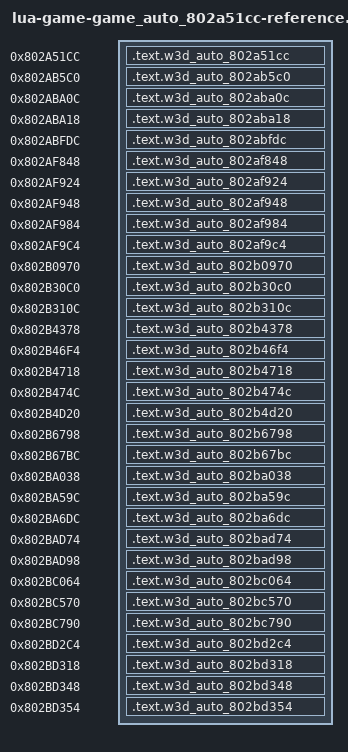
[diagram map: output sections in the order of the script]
/* Generated reference-only placements. All bodies are source-built. */
OUTPUT_FORMAT("elf32-powerpc")
OUTPUT_ARCH(powerpc)
ENTRY(w3d_auto_802a51cc)
_SDA_BASE_ = 0x804b2540;
_SDA2_BASE_ = 0x804c2540;
fn_8015FD1C = 0x8015fd1c;
fn_802B0668 = 0x802b0668;
fn_802B0990 = 0x802b0990;
fn_802B0FEC = 0x802b0fec;
fn_802B15E0 = 0x802b15e0;
fn_802B16C4 = 0x802b16c4;
fn_802B1BD0 = 0x802b1bd0;
fn_802B1F98 = 0x802b1f98;
fn_802B222C = 0x802b222c;
fn_802B2344 = 0x802b2344;
fn_802B38D4 = 0x802b38d4;
fn_802B4E10 = 0x802b4e10;
fn_802B9DE4 = 0x802b9de4;
fn_802BC1D0 = 0x802bc1d0;
fn_802BC1D4 = 0x802bc1d4;
fn_802BC570 = 0x802bc570;
fn_802BC5AC = 0x802bc5ac;
fn_802BC600 = 0x802bc600;
fn_802BD354 = 0x802bd354;
fn_802BDD24 = 0x802bdd24;
fn_802BFC64 = 0x802bfc64;
fn_80316270 = 0x80316270;
SECTIONS {
  .text.w3d_auto_802a51cc 0x802a51cc : { *(.text.w3d_auto_802a51cc) }
  .text.w3d_auto_802ab5c0 0x802ab5c0 : { *(.text.w3d_auto_802ab5c0) }
  .text.w3d_auto_802aba0c 0x802aba0c : { *(.text.w3d_auto_802aba0c) }
  .text.w3d_auto_802aba18 0x802aba18 : { *(.text.w3d_auto_802aba18) }
  .text.w3d_auto_802abfdc 0x802abfdc : { *(.text.w3d_auto_802abfdc) }
  .text.w3d_auto_802af848 0x802af848 : { *(.text.w3d_auto_802af848) }
  .text.w3d_auto_802af924 0x802af924 : { *(.text.w3d_auto_802af924) }
  .text.w3d_auto_802af948 0x802af948 : { *(.text.w3d_auto_802af948) }
  .text.w3d_auto_802af984 0x802af984 : { *(.text.w3d_auto_802af984) }
  .text.w3d_auto_802af9c4 0x802af9c4 : { *(.text.w3d_auto_802af9c4) }
  .text.w3d_auto_802b0970 0x802b0970 : { *(.text.w3d_auto_802b0970) }
  .text.w3d_auto_802b30c0 0x802b30c0 : { *(.text.w3d_auto_802b30c0) }
  .text.w3d_auto_802b310c 0x802b310c : { *(.text.w3d_auto_802b310c) }
  .text.w3d_auto_802b4378 0x802b4378 : { *(.text.w3d_auto_802b4378) }
  .text.w3d_auto_802b46f4 0x802b46f4 : { *(.text.w3d_auto_802b46f4) }
  .text.w3d_auto_802b4718 0x802b4718 : { *(.text.w3d_auto_802b4718) }
  .text.w3d_auto_802b474c 0x802b474c : { *(.text.w3d_auto_802b474c) }
  .text.w3d_auto_802b4d20 0x802b4d20 : { *(.text.w3d_auto_802b4d20) }
  .text.w3d_auto_802b6798 0x802b6798 : { *(.text.w3d_auto_802b6798) }
  .text.w3d_auto_802b67bc 0x802b67bc : { *(.text.w3d_auto_802b67bc) }
  .text.w3d_auto_802ba038 0x802ba038 : { *(.text.w3d_auto_802ba038) }
  .text.w3d_auto_802ba59c 0x802ba59c : { *(.text.w3d_auto_802ba59c) }
  .text.w3d_auto_802ba6dc 0x802ba6dc : { *(.text.w3d_auto_802ba6dc) }
  .text.w3d_auto_802bad74 0x802bad74 : { *(.text.w3d_auto_802bad74) }
  .text.w3d_auto_802bad98 0x802bad98 : { *(.text.w3d_auto_802bad98) }
  .text.w3d_auto_802bc064 0x802bc064 : { *(.text.w3d_auto_802bc064) }
  .text.w3d_auto_802bc570 0x802bc570 : { *(.text.w3d_auto_802bc570) }
  .text.w3d_auto_802bc790 0x802bc790 : { *(.text.w3d_auto_802bc790) }
  .text.w3d_auto_802bd2c4 0x802bd2c4 : { *(.text.w3d_auto_802bd2c4) }
  .text.w3d_auto_802bd318 0x802bd318 : { *(.text.w3d_auto_802bd318) }
  .text.w3d_auto_802bd348 0x802bd348 : { *(.text.w3d_auto_802bd348) }
  .text.w3d_auto_802bd354 0x802bd354 : { *(.text.w3d_auto_802bd354) }
  /DISCARD/ : { *(.text*) *(.rodata*) *(.data*) *(.bss*) *(.sdata*) *(.sbss*) *(.comment) }
}
